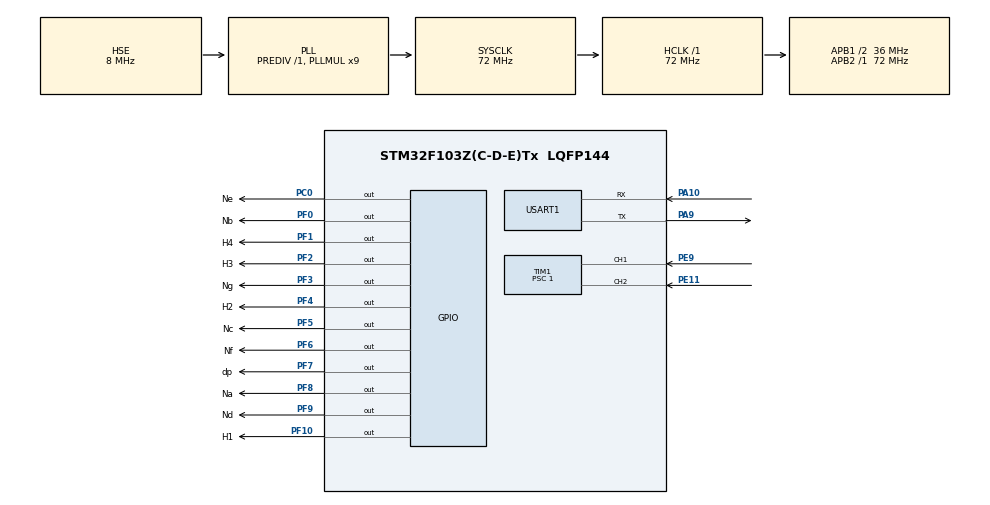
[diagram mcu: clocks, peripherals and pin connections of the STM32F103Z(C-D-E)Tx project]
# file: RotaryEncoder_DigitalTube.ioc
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Mcu.Family=STM32F1
Mcu.Name=STM32F103Z(C-D-E)Tx
Mcu.Package=LQFP144
NVIC.PriorityGroup=NVIC_PRIORITYGROUP_4
OSC_IN.Mode=HSE-External-Oscillator
OSC_IN.Signal=RCC_OSC_IN
OSC_OUT.Mode=HSE-External-Oscillator
OSC_OUT.Signal=RCC_OSC_OUT
PA10.Mode=Asynchronous
PA10.Signal=USART1_RX
PA13.Mode=Serial_Wire
PA13.Signal=SYS_JTMS-SWDIO
PA14.Mode=Serial_Wire
PA14.Signal=SYS_JTCK-SWCLK
PA9.Mode=Asynchronous
PA9.Signal=USART1_TX
PC0.GPIO_Label=Ne
PC0.GPIO_PuPd=GPIO_PULLDOWN
PC0.GPIO_Speed=GPIO_SPEED_FREQ_HIGH
PC0.PinState=GPIO_PIN_SET
PC0.Signal=GPIO_Output
PE11.Signal=S_TIM1_CH2
PE9.Signal=S_TIM1_CH1
PF0.GPIO_Label=Nb
PF0.GPIO_PuPd=GPIO_PULLDOWN
PF0.GPIO_Speed=GPIO_SPEED_FREQ_HIGH
PF0.PinState=GPIO_PIN_SET
PF0.Signal=GPIO_Output
PF1.GPIO_Label=H4
PF1.GPIO_PuPd=GPIO_PULLUP
PF1.GPIO_Speed=GPIO_SPEED_FREQ_HIGH
PF1.PinState=GPIO_PIN_SET
PF1.Signal=GPIO_Output
PF10.GPIO_Label=H1
PF10.GPIO_PuPd=GPIO_PULLUP
PF10.GPIO_Speed=GPIO_SPEED_FREQ_HIGH
PF10.PinState=GPIO_PIN_SET
PF10.Signal=GPIO_Output
PF2.GPIO_Label=H3
PF2.GPIO_PuPd=GPIO_PULLUP
PF2.GPIO_Speed=GPIO_SPEED_FREQ_HIGH
PF2.PinState=GPIO_PIN_SET
PF2.Signal=GPIO_Output
PF3.GPIO_Label=Ng
PF3.GPIO_PuPd=GPIO_PULLDOWN
PF3.GPIO_Speed=GPIO_SPEED_FREQ_HIGH
PF3.PinState=GPIO_PIN_SET
PF3.Signal=GPIO_Output
PF4.GPIO_Label=H2
PF4.GPIO_PuPd=GPIO_PULLUP
PF4.GPIO_Speed=GPIO_SPEED_FREQ_HIGH
PF4.PinState=GPIO_PIN_SET
PF4.Signal=GPIO_Output
PF5.GPIO_Label=Nc
PF5.GPIO_PuPd=GPIO_PULLDOWN
PF5.GPIO_Speed=GPIO_SPEED_FREQ_HIGH
PF5.PinState=GPIO_PIN_SET
PF5.Signal=GPIO_Output
PF6.GPIO_Label=Nf
PF6.GPIO_PuPd=GPIO_PULLDOWN
PF6.GPIO_Speed=GPIO_SPEED_FREQ_HIGH
PF6.PinState=GPIO_PIN_SET
PF6.Signal=GPIO_Output
PF7.GPIO_Label=dp
PF7.GPIO_PuPd=GPIO_PULLDOWN
PF7.GPIO_Speed=GPIO_SPEED_FREQ_HIGH
PF7.PinState=GPIO_PIN_SET
PF7.Signal=GPIO_Output
PF8.GPIO_Label=Na
PF8.GPIO_PuPd=GPIO_PULLDOWN
PF8.GPIO_Speed=GPIO_SPEED_FREQ_HIGH
PF8.PinState=GPIO_PIN_SET
PF8.Signal=GPIO_Output
PF9.GPIO_Label=Nd
PF9.GPIO_PuPd=GPIO_PULLDOWN
PF9.GPIO_Speed=GPIO_SPEED_FREQ_HIGH
PF9.PinState=GPIO_PIN_SET
PF9.Signal=GPIO_Output
ProjectManager.HeapSize=0x200
ProjectManager.StackSize=0x400
ProjectManager.TargetToolchain=STM32CubeIDE
RCC.AHBFreq_Value=72000000
RCC.APB1CLKDivider=RCC_HCLK_DIV2
RCC.APB1Freq_Value=36000000
RCC.APB1TimFreq_Value=72000000
RCC.APB2Freq_Value=72000000
RCC.APB2TimFreq_Value=72000000
RCC.HCLKFreq_Value=72000000
RCC.PLLMUL=RCC_PLL_MUL9
RCC.PLLSourceVirtual=RCC_PLLSOURCE_HSE
RCC.SYSCLKFreq_VALUE=72000000
RCC.SYSCLKSource=RCC_SYSCLKSOURCE_PLLCLK
RCC.USBFreq_Value=72000000
SH.S_TIM1_CH1.0=TIM1_CH1,Encoder_Interface
SH.S_TIM1_CH2.0=TIM1_CH2,Encoder_Interface
TIM1.EncoderMode=TIM_ENCODERMODE_TI1
TIM1.IC1Filter=15
TIM1.IC2Filter=15
TIM1.Prescaler=1
USART1.VirtualMode=VM_ASYNC
board=custom

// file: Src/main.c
/* USER CODE BEGIN Header */
/**
 ******************************************************************************
 * @file           : main.c
 * @brief          : Main program body
 ******************************************************************************
 * @attention
 *
 * Copyright (c) 2024 STMicroelectronics.
 * All rights reserved.
 *
 * This software is licensed under terms that can be found in the LICENSE file
 * in the root directory of this software component.
 * If no LICENSE file comes with this software, it is provided AS-IS.
 *
 ******************************************************************************
 */
/* USER CODE END Header */
#include <digital_tube.h>
#include "main.h"
#include "tim.h"
#include "usart.h"
#include "gpio.h"

/* USER CODE BEGIN Includes */
#include <stdio.h>
/* USER CODE END Includes */

void SystemClock_Config(void);

int main(void)
{

	/* MCU Configuration--------------------------------------------------------*/

	/* Reset of all peripherals, Initializes the Flash interface and the Systick. */
	HAL_Init();

	/* Configure the system clock */
	SystemClock_Config();

	/* Initialize all configured peripherals */
	MX_GPIO_Init();
	MX_TIM1_Init();
	MX_USART1_UART_Init();
	/* USER CODE BEGIN 2 */
	HAL_TIM_Encoder_Start(&htim1, TIM_CHANNEL_ALL);
	uint8_t count = 0;
	//char s[12] = "";

	HAL_GPIO_WritePin(dp_GPIO_Port, dp_Pin, RESET);
	/* USER CODE END 2 */

	/* Infinite loop */
	/* USER CODE BEGIN WHILE */
	while (1)
	{
		count = __HAL_TIM_GET_COUNTER(&htim1);
		//sprintf(s, "%d,%d,%d\r\n", (count % 1000 - count % 100) / 100,
		//		(count % 100 - count % 10) / 10, (count % 10 - count % 1) / 1);
		//HAL_UART_Transmit(&huart1, (uint8_t*) s, 12, 10);
		//HAL_Delay(250);
		H2_Show((count % 1000 - count % 100) / 100);
		H3_Show((count % 100 - count % 10) / 10);
		H4_Show((count % 10 - count % 1) / 1);
		/* USER CODE END WHILE */

	}
}

void SystemClock_Config(void)
{
	RCC_OscInitTypeDef RCC_OscInitStruct =
	{ 0 };
	RCC_ClkInitTypeDef RCC_ClkInitStruct =
	{ 0 };

	/** Initializes the RCC Oscillators according to the specified parameters
	 * in the RCC_OscInitTypeDef structure.
	 */
	RCC_OscInitStruct.OscillatorType = RCC_OSCILLATORTYPE_HSE;
	RCC_OscInitStruct.HSEState = RCC_HSE_ON;
	RCC_OscInitStruct.HSEPredivValue = RCC_HSE_PREDIV_DIV1;
	RCC_OscInitStruct.HSIState = RCC_HSI_ON;
	RCC_OscInitStruct.PLL.PLLState = RCC_PLL_ON;
	RCC_OscInitStruct.PLL.PLLSource = RCC_PLLSOURCE_HSE;
	RCC_OscInitStruct.PLL.PLLMUL = RCC_PLL_MUL9;
	if (HAL_RCC_OscConfig(&RCC_OscInitStruct) != HAL_OK)
	{
		Error_Handler();
	}

	/** Initializes the CPU, AHB and APB buses clocks
	 */
	RCC_ClkInitStruct.ClockType = RCC_CLOCKTYPE_HCLK | RCC_CLOCKTYPE_SYSCLK
			| RCC_CLOCKTYPE_PCLK1 | RCC_CLOCKTYPE_PCLK2;
	RCC_ClkInitStruct.SYSCLKSource = RCC_SYSCLKSOURCE_PLLCLK;
	RCC_ClkInitStruct.AHBCLKDivider = RCC_SYSCLK_DIV1;
	RCC_ClkInitStruct.APB1CLKDivider = RCC_HCLK_DIV2;
	RCC_ClkInitStruct.APB2CLKDivider = RCC_HCLK_DIV1;

	if (HAL_RCC_ClockConfig(&RCC_ClkInitStruct, FLASH_LATENCY_2) != HAL_OK)
	{
		Error_Handler();
	}
}

void Error_Handler(void)
{
	__disable_irq();
	while (1)
	{
	}
}
